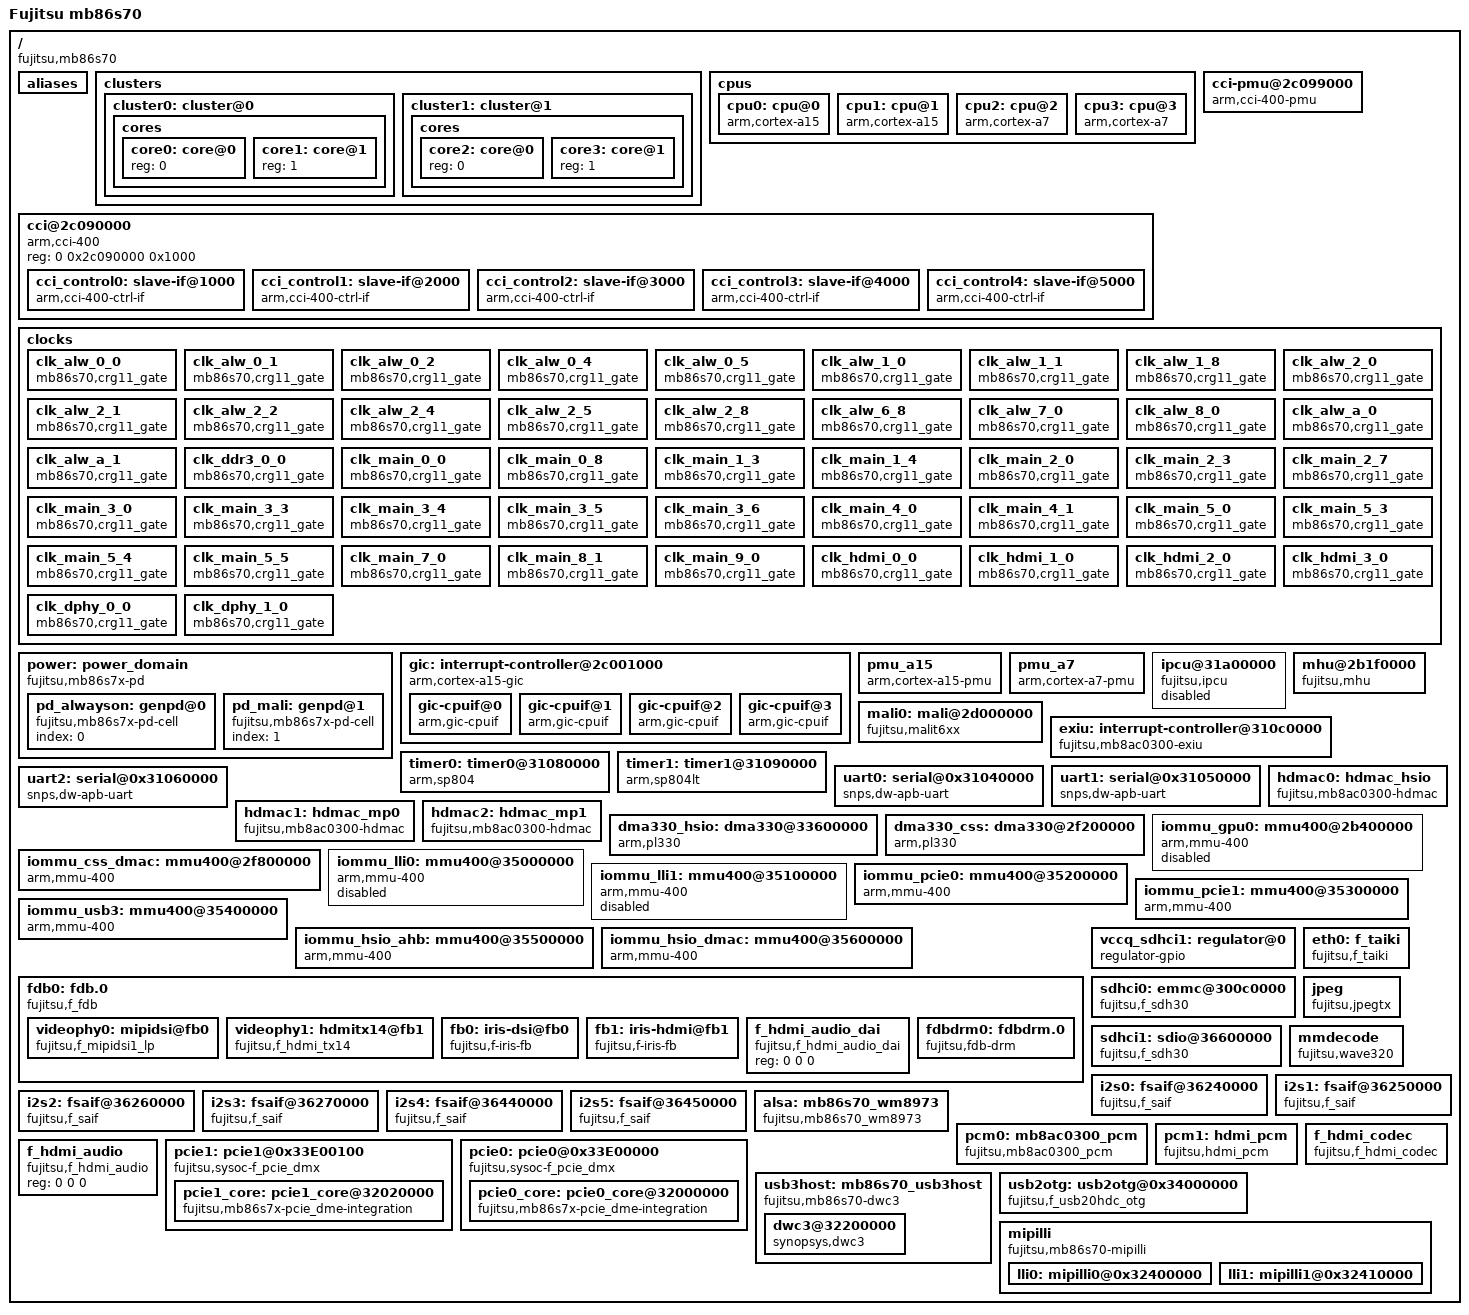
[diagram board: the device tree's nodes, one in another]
/*
 * Copyright (C) 2013-2015 Linaro, LTD for FUJITSU SEMICONDUCTOR LIMITED
 * Copyright (C) 2015-2016 Socionext Inc.
 *
 * This program is free software; you can redistribute it and/or modify
 * it under the terms of the GNU General Public License version 2 as
 * published by the Free Software Foundation.
 */

/ {
	model = "Fujitsu mb86s70";
	compatible = "fujitsu,mb86s70";
	interrupt-parent = <&gic>;
	#address-cells = <2>;
	#size-cells = <1>;

	aliases {
		serial0 = &uart0;
		serial1 = &uart1;
		serial2 = &uart2;
	};

	clusters {
		#address-cells = <1>;
		#size-cells = <0>;

		cluster0: cluster@0 { /* A15s */
			reg = <0>;
			freqs = <1600000000>;
			cores {
				#address-cells = <1>;
				#size-cells = <0>;

				core0: core@0 {
					reg = <0>;
				};

				core1: core@1 {
					reg = <1>;
				};
			};
		};

		cluster1: cluster@1 {
			reg = <1>;
			freqs = <800000000>;
			cores {
				#address-cells = <1>;
				#size-cells = <0>;
				core2: core@0 {
					reg = <0>;
				};

				core3: core@1 {
					reg = <1>;
				};
			};
		};
	};

	cpus {
		#address-cells = <1>;
		#size-cells = <0>;

		cpu0: cpu@0 {
			device_type = "cpu";
			compatible = "arm,cortex-a15";
			reg = <0>;
			cluster = <&cluster0>;
			core = <&core0>;
			cci-control-port = <&cci_control4>;
			clock-frequency = <1600000000>;
			operating-points = <
				1600000	1020000
			>;
			clock-latency = <1000000>;
		};

		cpu1: cpu@1 {
			device_type = "cpu";
			compatible = "arm,cortex-a15";
			reg = <1>;
			cluster = <&cluster0>;
			core = <&core1>;
			cci-control-port = <&cci_control4>;
			clock-frequency = <1600000000>;
			operating-points = <
				1600000	1020000
			>;
			clock-latency = <1000000>;
		};

		cpu2: cpu@2 {
			device_type = "cpu";
			compatible = "arm,cortex-a7";
			reg = <0x100>;
			cluster = <&cluster1>;
			core = <&core2>;
			cci-control-port = <&cci_control3>;
			clock-frequency = <800000000>;
			operating-points = <
				800000 900000
			>;
			clock-latency = <1000000>;
		};

		cpu3: cpu@3 {
			device_type = "cpu";
			compatible = "arm,cortex-a7";
			reg = <0x101>;
			cluster = <&cluster1>;
			core = <&core3>;
			cci-control-port = <&cci_control3>;
			clock-frequency = <800000000>;
			operating-points = <
				800000 900000
			>;
			clock-latency = <1000000>;
		};
	};

	cci@2c090000 {
		compatible = "arm,cci-400", "arm,cci";
		#address-cells = <1>;
		#size-cells = <1>;
		reg = <0 0x2c090000 0x1000>;
		ranges = <0x0 0x0 0x2c090000 0x10000>;

		cci_control0: slave-if@1000 {
			compatible = "arm,cci-400-ctrl-if";
			interface-type = "ace-lite";
			reg = <0x1000 0x1000>;
		};

		cci_control1: slave-if@2000 {
			compatible = "arm,cci-400-ctrl-if";
			interface-type = "ace-lite";
			reg = <0x2000 0x1000>;
		};

		cci_control2: slave-if@3000 {
			compatible = "arm,cci-400-ctrl-if";
			interface-type = "ace-lite";
			reg = <0x3000 0x1000>;
		};

		cci_control3: slave-if@4000 {
			compatible = "arm,cci-400-ctrl-if";
			interface-type = "ace";
			reg = <0x4000 0x1000>;
		};

		cci_control4: slave-if@5000 {
 			compatible = "arm,cci-400-ctrl-if";
 			interface-type = "ace";
 			reg = <0x5000 0x1000>;
 		};

	};

	cci-pmu@2c099000 {
		compatible = "arm,cci-400-pmu";
		reg = <0 0x2c099000 0x5000>;
		interrupts = <0 77 4>,
				<0 77 4>,
				<0 77 4>,
				<0 77 4>,
				<0 77 4>;
	};

	/**
	 * cntrlr : 0->ALW, 1->DDR3, 2->MAIN, 3->CA15, 4->HDMI, 5->DPHY
	 * port : [0,7] -> Gateable Clock Ports.  [8]->UngatedCLK
	 */
	clocks {
		clk_alw_0_0: clk_alw_0_0 {
			#clock-cells = <0>;
			compatible = "mb86s70,crg11_gate";
			cntrlr = <0>;
			domain = <0>;
			port = <0>;
		};
		clk_alw_0_1: clk_alw_0_1 {
			#clock-cells = <0>;
			compatible = "mb86s70,crg11_gate";
			cntrlr = <0>;
			domain = <0>;
			port = <1>;
		};
		clk_alw_0_2: clk_alw_0_2 {
			#clock-cells = <0>;
			compatible = "mb86s70,crg11_gate";
			cntrlr = <0>;
			domain = <0>;
			port = <2>;
		};
		clk_alw_0_4: clk_alw_0_4 {
			#clock-cells = <0>;
			compatible = "mb86s70,crg11_gate";
			cntrlr = <0>;
			domain = <0>;
			port = <4>;
		};
		clk_alw_0_5: clk_alw_0_5 {
			#clock-cells = <0>;
			compatible = "mb86s70,crg11_gate";
			cntrlr = <0>;
			domain = <0>;
			port = <5>;
		};
		clk_alw_1_0: clk_alw_1_0 {
			#clock-cells = <0>;
			compatible = "mb86s70,crg11_gate";
			cntrlr = <0>;
			domain = <1>;
			port = <0>;
		};
		clk_alw_1_1: clk_alw_1_1 {
			#clock-cells = <0>;
			compatible = "mb86s70,crg11_gate";
			cntrlr = <0>;
			domain = <1>;
			port = <1>;
		};
		clk_alw_1_8: clk_alw_1_8 {
			#clock-cells = <0>;
			compatible = "mb86s70,crg11_gate";
			cntrlr = <0>;
			domain = <1>;
			port = <8>;
		};
		clk_alw_2_0: clk_alw_2_0 {
			#clock-cells = <0>;
			compatible = "mb86s70,crg11_gate";
			cntrlr = <0>;
			domain = <2>;
			port = <0>;
		};
		clk_alw_2_1: clk_alw_2_1 {
			#clock-cells = <0>;
			compatible = "mb86s70,crg11_gate";
			cntrlr = <0>;
			domain = <2>;
			port = <1>;
		};
		clk_alw_2_2: clk_alw_2_2 {
			#clock-cells = <0>;
			compatible = "mb86s70,crg11_gate";
			cntrlr = <0>;
			domain = <2>;
			port = <2>;
		};
		clk_alw_2_4: clk_alw_2_4 {
			#clock-cells = <0>;
			compatible = "mb86s70,crg11_gate";
			cntrlr = <0>;
			domain = <2>;
			port = <4>;
		};
		clk_alw_2_5: clk_alw_2_5 {
			#clock-cells = <0>;
			compatible = "mb86s70,crg11_gate";
			cntrlr = <0>;
			domain = <2>;
			port = <5>;
		};
		clk_alw_2_8: clk_alw_2_8 {
			#clock-cells = <0>;
			compatible = "mb86s70,crg11_gate";
			cntrlr = <0>;
			domain = <2>;
			port = <8>;
		};
		clk_alw_6_8: clk_alw_6_8 {
			#clock-cells = <0>;
			compatible = "mb86s70,crg11_gate";
			cntrlr = <0>;
			domain = <6>;
			port = <8>;
		};

		clk_alw_7_0: clk_alw_7_0 {
			#clock-cells = <0>;
			compatible = "mb86s70,crg11_gate";
			cntrlr = <0>;
			domain = <7>;
			port = <0>;
		};
		clk_alw_8_0: clk_alw_8_0 {
			#clock-cells = <0>;
			compatible = "mb86s70,crg11_gate";
			cntrlr = <0>;
			domain = <8>;
			port = <0>;
		};
		clk_alw_a_0: clk_alw_a_0 {
			#clock-cells = <0>;
			compatible = "mb86s70,crg11_gate";
			cntrlr = <0>;
			domain = <0x0a>;
			port = <0>;
		};
		clk_alw_a_1: clk_alw_a_1 {
			#clock-cells = <0>;
			compatible = "mb86s70,crg11_gate";
			cntrlr = <0>;
			domain = <0x0a>;
			port = <1>;
		};
		clk_ddr3_0_0: clk_ddr3_0_0 {
			#clock-cells = <0>;
			compatible = "mb86s70,crg11_gate";
			cntrlr = <1>;
			domain = <0>;
			port = <0>;
		};

		clk_main_0_0: clk_main_0_0 {
			#clock-cells = <0>;
			compatible = "mb86s70,crg11_gate";
			cntrlr = <2>;
			domain = <0>;
			port = <0>;
		};
		clk_main_0_8: clk_main_0_8 {
			#clock-cells = <0>;
			compatible = "mb86s70,crg11_gate";
			cntrlr = <2>;
			domain = <0>;
			port = <8>;
		};
		clk_main_1_3: clk_main_1_3 {
			#clock-cells = <0>;
			compatible = "mb86s70,crg11_gate";
			cntrlr = <2>;
			domain = <1>;
			port = <3>;
		};
		clk_main_1_4: clk_main_1_4 {
			#clock-cells = <0>;
			compatible = "mb86s70,crg11_gate";
			cntrlr = <2>;
			domain = <1>;
			port = <4>;
		};
		clk_main_2_0: clk_main_2_0 {
			#clock-cells = <0>;
			compatible = "mb86s70,crg11_gate";
			cntrlr = <2>;
			domain = <2>;
			port = <0>;
		};
		clk_main_2_3: clk_main_2_3 {
			#clock-cells = <0>;
			compatible = "mb86s70,crg11_gate";
			cntrlr = <2>;
			domain = <2>;
			port = <3>;
		};
		clk_main_2_7: clk_main_2_7 {
			#clock-cells = <0>;
			compatible = "mb86s70,crg11_gate";
			cntrlr = <2>;
			domain = <2>;
			port = <7>;
		};
		clk_main_3_0: clk_main_3_0 {
			#clock-cells = <0>;
			compatible = "mb86s70,crg11_gate";
			cntrlr = <2>;
			domain = <3>;
			port = <0>;
		};
		clk_main_3_3: clk_main_3_3 {
			#clock-cells = <0>;
			compatible = "mb86s70,crg11_gate";
			cntrlr = <2>;
			domain = <3>;
			port = <3>;
		};
		clk_main_3_4: clk_main_3_4 {
			#clock-cells = <0>;
			compatible = "mb86s70,crg11_gate";
			cntrlr = <2>;
			domain = <3>;
			port = <4>;
		};
		clk_main_3_5: clk_main_3_5 {
			#clock-cells = <0>;
			compatible = "mb86s70,crg11_gate";
			cntrlr = <2>;
			domain = <3>;
			port = <5>;
		};
		clk_main_3_6: clk_main_3_6 {
			#clock-cells = <0>;
			compatible = "mb86s70,crg11_gate";
			cntrlr = <2>;
			domain = <3>;
			port = <6>;
		};
		clk_main_4_0: clk_main_4_0 {
			#clock-cells = <0>;
			compatible = "mb86s70,crg11_gate";
			cntrlr = <2>;
			domain = <4>;
			port = <0>;
		};
		clk_main_4_1: clk_main_4_1 {
			#clock-cells = <0>;
			compatible = "mb86s70,crg11_gate";
			cntrlr = <2>;
			domain = <4>;
			port = <1>;
		};
		clk_main_5_0: clk_main_5_0 {
			#clock-cells = <0>;
			compatible = "mb86s70,crg11_gate";
			cntrlr = <2>;
			domain = <5>;
			port = <0>;
		};
		clk_main_5_3: clk_main_5_3 {
			#clock-cells = <0>;
			compatible = "mb86s70,crg11_gate";
			cntrlr = <2>;
			domain = <5>;
			port = <3>;
		};
		clk_main_5_4: clk_main_5_4 {
			#clock-cells = <0>;
			compatible = "mb86s70,crg11_gate";
			cntrlr = <2>;
			domain = <5>;
			port = <4>;
		};
		clk_main_5_5: clk_main_5_5 {
			#clock-cells = <0>;
			compatible = "mb86s70,crg11_gate";
			cntrlr = <2>;
			domain = <5>;
			port = <5>;
		};
		clk_main_7_0: clk_main_7_0 {
			#clock-cells = <0>;
			compatible = "mb86s70,crg11_gate";
			cntrlr = <2>;
			domain = <7>;
			port = <0>;
		};
		clk_main_8_1: clk_main_8_1 {
			#clock-cells = <0>;
			compatible = "mb86s70,crg11_gate";
			cntrlr = <2>;
			domain = <8>;
			port = <1>;
		};
		clk_main_9_0: clk_main_9_0 {
			#clock-cells = <0>;
			compatible = "mb86s70,crg11_gate";
			cntrlr = <2>;
			domain = <9>;
			port = <0>;
		};
		clk_hdmi_0_0: clk_hdmi_0_0 {
			#clock-cells = <0>;
			compatible = "mb86s70,crg11_gate";
			cntrlr = <4>;
			domain = <0>;
			port = <0>;
		};
		clk_hdmi_1_0: clk_hdmi_1_0 {
			#clock-cells = <0>;
			compatible = "mb86s70,crg11_gate";
			cntrlr = <4>;
			domain = <1>;
			port = <0>;
		};
		clk_hdmi_2_0: clk_hdmi_2_0 {
			#clock-cells = <0>;
			compatible = "mb86s70,crg11_gate";
			cntrlr = <4>;
			domain = <2>;
			port = <0>;
		};
		clk_hdmi_3_0: clk_hdmi_3_0 {
			#clock-cells = <0>;
			compatible = "mb86s70,crg11_gate";
			cntrlr = <4>;
			domain = <3>;
			port = <0>;
		};

		clk_dphy_0_0: clk_dphy_0_0 {
			#clock-cells = <0>;
			compatible = "mb86s70,crg11_gate";
			cntrlr = <5>;
			domain = <0>;
			port = <0>;
		};
		clk_dphy_1_0: clk_dphy_1_0 {
			#clock-cells = <0>;
			compatible = "mb86s70,crg11_gate";
			cntrlr = <5>;
			domain = <1>;
			port = <0>;
		};
	};

	power: power_domain {
		compatible = "fujitsu,mb86s7x-pd";
		#power-domain-cells = <1>;
		#address-cells = <2>;
		#size-cells = <1>;
		ranges;

		pd_alwayson: genpd@0 {
			compatible = "fujitsu,mb86s7x-pd-cell";
			index = <0>;
		};
		pd_mali: genpd@1 {
			compatible = "fujitsu,mb86s7x-pd-cell";
			index = <1>;
		};
	};

	gic: interrupt-controller@2c001000 {
		compatible = "arm,cortex-a15-gic", "arm,cortex-a9-gic";
		#interrupt-cells = <3>;
		interrupt-controller;
		reg = <0 0x2c001000 0x1000>,
		      <0 0x2c002000 0x1000>,
		      <0 0x2c004000 0x2000>,
		      <0 0x2c006000 0x2000>;
		interrupts = <1 9 0xf04>;

		gic-cpuif@0 {
			compatible = "arm,gic-cpuif";
			cpuif-id = <0>;
			cpu = <&cpu0>;
		};
		gic-cpuif@1 {
			compatible = "arm,gic-cpuif";
			cpuif-id = <1>;
			cpu = <&cpu1>;
		};
		gic-cpuif@2 {
			compatible = "arm,gic-cpuif";
			cpuif-id = <2>;
			cpu = <&cpu2>;
		};
		gic-cpuif@3 {
			compatible = "arm,gic-cpuif";
			cpuif-id = <3>;
			cpu = <&cpu3>;
		};
	};

	pmu_a15 {
		compatible = "arm,cortex-a15-pmu";
		cluster  = <&cluster0>;
		interrupts = <0 2 4>,
			     <0 6 4>;
	};

	pmu_a7 {
		compatible = "arm,cortex-a7-pmu";
		cluster  = <&cluster1>;
		interrupts = <0 18 4>,
			     <0 22 4>;
	};

	ipcu@31a00000 {
		#clock-cells = <1>;
		compatible = "fujitsu,ipcu";
		status = "disabled";
		mboxes = <8>;
		reg = <0 0x31A00000 0x960>;
		interrupts = <0 152 4>, /* A15 CPU 0 */
			     <0 153 4>, /* A15 CPU 1 */
			     <0 154 4>,
			     <0 155 4>,
			     <0 156 4>, /* A7 CPU 0 */
			     <0 157 4>, /* A7 CPU 1 */
			     <0 158 4>,
			     <0 159 4>;
		clocks = <&clk_alw_2_1>;
	};

	mhu@2b1f0000 {
		compatible = "fujitsu,mhu";
		reg = <0 0x2B1F0000 0x1000>;
		interrupts = <0 36 4>, /* LP Non-Sec */
			     <0 35 4>, /* HP Non-Sec */
			     <0 37 4>; /* Secure */
		clocks = <&clk_alw_2_1>;
		clock-names = "clk";
	};

	mali0: mali@2d000000 {
		compatible = "fujitsu,malit6xx";
		reg = <0 0x2d000000 0x10000>;
		interrupts = <0 33 4>, /* Mali JOB */
			     <0 34 4>, /* Mali MMU */
			     <0 32 4>; /* Mali GPU */
                interrupt-names = "JOB", "MMU", "GPU";
		clocks = <&clk_main_7_0>, <&clk_main_2_0>, <&clk_main_0_0>, <&clk_main_4_0>;
		clock-names = "g3d", "aclk_g3d", "mout_gpll", "fout_gpll";
		#stream-id-cells = <0>;
		power-domains = <&power 1>;
		cci-control-port = <&cci_control2>;
	};

	exiu: interrupt-controller@310c0000 {
		compatible = "fujitsu,mb8ac0300-exiu";
		reg = <0 0x310c0000 0x1000>;
		exiu_irq_base0 = <112>;
		exiu_irq_base1 = <128>;
		clocks = <&clk_alw_2_1>;
	};

	timer0: timer0@31080000 {
		#clock-cells = <1>;
		compatible = "arm,sp804";
		reg = <0 0x31080000 0x10000>;
		interrupts = <0 324 4>,
			     <0 325 4>;
		clocks = <&clk_alw_6_8>;
	};

	timer1: timer1@31090000 {
		#clock-cells = <1>;
		compatible = "arm,sp804lt";
		reg = <0 0x31090000 0x20000>;
		interrupts = <0 328 4>,
			     <0 329 4>,
			     <0 332 4>,
			     <0 333 4>;
		clocks = <&clk_alw_6_8>;
	};

	uart0: serial@0x31040000 {
		#clock-cells = <1>;
		compatible = "snps,dw-apb-uart";
		reg = <0 0x31040000 0x100>;
		interrupts = <0 320 0x4>;
		clock-frequency = <62500000>;
		reg-io-width = <4>;
		reg-shift = <2>;
		clocks = <&clk_alw_2_1>;
		clock-names = "sclk";
	};

	uart1: serial@0x31050000 {
		#clock-cells = <1>;
		compatible = "snps,dw-apb-uart";
		reg = <0 0x31050000 0x100>;
		interrupts = <0 321 0x4>;
		clock-frequency = <62500000>;
		reg-io-width = <4>;
		reg-shift = <2>;
		clocks = <&clk_alw_2_1>;
		clock-names = "sclk";
	};

	uart2: serial@0x31060000 {
		#clock-cells = <1>;
		compatible = "snps,dw-apb-uart";
		reg = <0 0x31060000 0x100>;
		interrupts = <0 322 0x4>;
		clock-frequency = <62500000>;
		reg-io-width = <4>;
		reg-shift = <2>;
		clocks = <&clk_alw_2_1>;
		clock-names = "sclk";
	};

	hdmac0: hdmac_hsio {
		compatible = "fujitsu,mb8ac0300-hdmac";
		reg = <0 0x34080000 0x1000>;
		interrupts = <0 128 0x4>,
			     <0 129 0x4>;
		clocks = <&clk_alw_2_1>, <&clk_main_2_3>;
		channels = <2>;
		chip = <0>;
		rotation = <1>;
	};

	hdmac1: hdmac_mp0 {
		compatible = "fujitsu,mb8ac0300-hdmac";
		reg = <0 0x36200000 0x1000>;
		interrupts = <0 112 0x4>,
			     <0 113 0x4>,
			     <0 114 0x4>,
			     <0 115 0x4>,
			     <0 116 0x4>,
			     <0 117 0x4>,
			     <0 118 0x4>,
			     <0 119 0x4>;
		clocks = <&clk_main_3_6>;
		channels = <8>;
		chip = <1>;
		rotation = <1>;
	};

	hdmac2: hdmac_mp1 {
		compatible = "fujitsu,mb8ac0300-hdmac";
		reg = <0 0x36400000 0x1000>;
		interrupts = <0 120 0x4>,
			     <0 121 0x4>,
			     <0 122 0x4>,
			     <0 123 0x4>;
		clocks = <&clk_main_3_6>;
		channels = <4>;
		chip = <2>;
		rotation = <1>;
	};

	dma330_hsio: dma330@33600000 {
		compatible = "arm,pl330", "arm,primecell";
		reg = <0 0x33600000 0x1000>;
		interrupts = <0 144 4>,
				<0 145 4>,
				<0 146 4>,
				<0 147 4>;
		clocks = <&clk_main_0_8>;
		clock-names = "apb_pclk";
		copy-align = <128>;
		#dma-cells = <1>;
		#dma-channels = <4>;
		#dma-requests = <1>;
		#stream-id-cells = <2>;
		iova-start = <0x00000000>;
		iova-range = <0x1 0x00000000>;
	};

	dma330_css: dma330@2f200000 {
		compatible = "arm,pl330", "arm,primecell";
		reg = <0 0x2f200000 0x1000>;
		interrupts = <0 136 4>,
				<0 137 4>,
				<0 138 4>,
				<0 139 4>,
				<0 140 4>,
				<0 141 4>,
				<0 142 4>,
				<0 143 4>;
		clocks = <&clk_main_0_8>;
		clock-names = "apb_pclk";
		copy-align = <128>;
		#dma-cells = <1>;
		#dma-channels = <8>;
		#dma-requests = <32>;
		#stream-id-cells = <2>;
		iova-start = <0x00000000>;
		iova-range = <0x1 0x00000000>;
	};

	iommu_gpu0: mmu400@2b400000 {
		status = "disabled";
		compatible = "arm,mmu-400";
		reg = <0 0x2b400000 0x10000>;
		#global-interrupts = <1>;
		interrupts = <0 38 4>, <0 39 4>;
		mmu-masters = <&mali0>;
		stream-ids = <0>;
	};
	iommu_css_dmac: mmu400@2f800000 {
		compatible = "arm,mmu-400";
		reg = <0 0x2f800000 0x10000>;
		#global-interrupts = <1>;
		interrupts = <0 64 4>, <0 65 4>;
		mmu-masters = <&dma330_css 0 1>;
		coherent_table_walk;
		stream-ids = <0>;
	};
	iommu_lli0: mmu400@35000000 {
		status = "disabled";
		compatible = "arm,mmu-400";
		reg = <0 0x35000000 0x10000>;
		#global-interrupts = <1>;
		interrupts = <0 66 4>, <0 67 4>;
		mmu-masters = <&lli0>;
		stream-ids = <0>;
	};
	iommu_lli1: mmu400@35100000 {
		status = "disabled";
		compatible = "arm,mmu-400";
		reg = <0 0x35100000 0x10000>;
		#global-interrupts = <1>;
		interrupts = <0 68 4>, <0 69 4>;
		mmu-masters = <&lli1>;
		stream-ids = <0>;
	};
	iommu_pcie0: mmu400@35200000 {
		compatible = "arm,mmu-400";
		reg = <0 0x35200000 0x10000>;
		#global-interrupts = <1>;
		interrupts = <0 71 4>, <0 70 4>;
		mmu-masters = <&pcie0 0 1>;
		stream-ids = <0>;
	};
	iommu_pcie1: mmu400@35300000 {
		compatible = "arm,mmu-400";
		reg = <0 0x35300000 0x10000>;
		#global-interrupts = <1>;
		interrupts = <0 73 4>, <0 72 4>;
		mmu-masters = <&pcie1 0 1>;
		stream-ids = <0>;
	};
	iommu_usb3: mmu400@35400000 {
		compatible = "arm,mmu-400";
		reg = <0 0x35400000 0x10000>;
		#global-interrupts = <1>;
		interrupts = <0 75 4>, <0 74 4>;
		mmu-masters = <&usb3host 0 1>;
		stream-ids = <0>;
	};
	iommu_hsio_ahb: mmu400@35500000 {
		compatible = "arm,mmu-400";
		reg = <0 0x35500000 0x10000>;
		#global-interrupts = <1>;
		interrupts = <0 77 4>, <0 76 4>;
		mmu-masters = <&usb2otg 0 1>;
		stream-ids = <0>, <0>;
	};
	iommu_hsio_dmac: mmu400@35600000 {
		compatible = "arm,mmu-400";
		reg = <0 0x35600000 0x10000>;
		#global-interrupts = <1>;
		interrupts = <0 79 4>, <0 78 4>;
		mmu-masters = <&dma330_hsio 0 1>;
		stream-ids = <0>;
	};

	fdb0: fdb.0 {
		compatible = "fujitsu,f_fdb",
			     "simple-bus";
		id = <0>;
		#address-cells = <2>;
		#size-cells = <1>;
		#stream-id-cells = <2>;
		iova-start = <0x90000000>;
		iova-range = <0x0 0x50000000>;
		ranges;

		/* dsi PHY --  IP2 doc p453 */
		videophy0: mipidsi@fb0 {
			compatible = "fujitsu,f_mipidsi1_lp";
			reg = <0 0x37700000 0x8000>;
			interrupts = <0 305 0x4>;
			sources = <1>; /* bitfield of fbs can be driven by */
			clocks = <&clk_dphy_0_0>, <&clk_dphy_1_0>, <&clk_main_5_3>;
			clock-names = "pllclk", "dpiclk", "pclk";
			simple-bind = <&fb0>;
		};

		/* hdmi PHY -- IP2 doc p71 */
		videophy1: hdmitx14@fb1 {
			compatible = "fujitsu,f_hdmi_tx14";
			reg = <0 0x37600000 0x8000>;
			interrupts = <0 304 0x4>;
			sources = <2>; /* bitfield of fbs can be driven by */
			clocks = <&clk_hdmi_0_0>, <&clk_main_5_0>, <&clk_hdmi_1_0>;
			clock-names = "pllclk", "pclk", "dpiclk";
			simple-bind = <&fb1>;
		};


		/* DSI IRIS */
		fb0: iris-dsi@fb0 {
			compatible = "fujitsu,f-iris-fb";
			reg = <0 0x37020000 0x8000>;
			interrupts = <0 212 0x4>,
				     <0 213 0x4>,
				     <0 214 0x4>,
				     <0 215 0x4>,
				     <0 216 0x4>,
				     <0 217 0x4>,
				     <0 218 0x4>,
				     <0 219 0x4>,
				     <0 220 0x4>,
				     <0 221 0x4>,
				     <0 222 0x4>,
				     <0 223 0x4>,
				     <0 224 0x4>,
				     <0 225 0x4>,
				     <0 226 0x4>,
				     <0 227 0x4>;
			id = <0>;
			simple = <0>;
			perf-mode = <1>;
			/* EVB LCD timings / resolution (mipidsi) */
			mode = "768x1280x32bpp"; /* 768x1280x16bpp also possible */
			/* not possible to offset start of dsi px stream, have to offset fb start */
			h-pixels-fb-offset = <12>;
			clocks = <&clk_dphy_1_0>, <&clk_main_1_3>, <&clk_main_3_3>;
			clock-names = "clk1", "clk2", "clk3";
		};

		/* HDMI IRIS */
		fb1: iris-hdmi@fb1 {
			status = "okay";
			compatible = "fujitsu,f-iris-fb";
			reg = <0 0x37000000 0x8000>;
			interrupts = <0 192 0x4>,
				     <0 193 0x4>,
				     <0 194 0x4>,
				     <0 195 0x4>,
				     <0 196 0x4>,
				     <0 197 0x4>,
				     <0 198 0x4>,
				     <0 199 0x4>,
				     <0 200 0x4>,
				     <0 201 0x4>,
				     <0 202 0x4>,
				     <0 203 0x4>,
				     <0 204 0x4>,
				     <0 205 0x4>,
				     <0 206 0x4>,
				     <0 207 0x4>;
			id = <1>;
			simple = <0>;
			perf-mode = <1>;
			/* colourbars = <1>; */
			clocks = <&clk_hdmi_0_0>, <&clk_hdmi_1_0>, <&clk_main_1_4>, <&clk_main_3_4>, <&clk_main_5_4>, <&clk_alw_7_0>, <&clk_alw_8_0>;
			clock-names = "clk1", "clk2", "clk3", "clk4", "clk5", "clk6", "clk7";
		};

		f_hdmi_audio_dai: f_hdmi_audio_dai {
			compatible = "fujitsu,f_hdmi_audio_dai";
			reg = <0 0 0>;
		};

		fdbdrm0: fdbdrm.0 {
			status = "okay";
			compatible = "fujitsu,fdb-drm";
			bind = <&fb0>, <&fb1>;
			registrations = <4>; /* wait for this many children */
			default-bpp = <32>; /* set to 16 if 16-bit LCD mode selected */
		};
	};

	vccq_sdhci1: regulator@0 {
		compatible = "regulator-gpio";
		regulator-name = "SDHCI1 VccQ";
		regulator-min-microvolt = <1800000>;
		regulator-max-microvolt = <3300000>;
		gpios = <&gpio0 7 0>;
		gpios-states = <1>;
		states = <3300000 1
			  1800000 0>;
	};

	sdhci0: emmc@300c0000 {
		compatible = "fujitsu,f_sdh30";
		reg = <0 0x300c0000 0x1000>;
		interrupts = <0 164 0x4>,
			     <0 165 0x4>;
		bus-width = <8>;
		clocks = <&clk_alw_1_8>, <&clk_alw_6_8>;
		clock-names = "sd_sd4clk", "sd_bclk";
		tuning_count_default = <0xA>;
	};

	sdhci1: sdio@36600000 {
		compatible = "fujitsu,f_sdh30";
		reg = <0 0x36600000 0x1000>;
		interrupts = <0 172 0x4>,
			     <0 173 0x4>;
		vqmmc-supply = <&vccq_sdhci1>;
		/*
		 * bitmap of EVB board revisions lacking 1.8V capability
		 * b0 = rev 0, b1 = rev 1, etc
		 */
		revs-no-1v8 = <1>;
		inverted-write-protect;
		clocks = <&clk_hdmi_2_0>, <&clk_hdmi_3_0>;
		clock-names = "sd_sd4clk", "sd_bclk";
		#stream-id-cells = <2>;
		iova-start = <0x90000000>;
		iova-range = <0x0 0x50000000>;
		tuning_count_default = <0xA>;
	};

	eth0: f_taiki {
                compatible = "fujitsu,f_taiki";
                id = <0>;
                default_mac = < 0xa4 0x17 0x31 0x00 0x00 0xed >;
		reg = <0 0x31600000 0x10000>;
		interrupts = <0 163 0x4>;
		/* fake clocks */
		clocks = <&clk_alw_1_8>, <&clk_alw_1_8>, <&clk_alw_1_8>;
		clock-names = "h_clk", "osc_clk", "pclk";
		phy-interface = "RGMII";
		phy-dev-addr = <1>;
		phy-status-poll-interval-ms = <500>;
		link-speed = "1G";
		half-duplex = <0>;
		flow-control = <1>;
		use-jumbo = <1>;
		gpio-phy-enable = <14>;
		gpio-phy-nrst = <13>;
	};

	jpeg: jpeg {
		compatible = "fujitsu,jpegtx";
		reg = <0 0x36020000 0x10000>;
		id = <0>;
		interrupts = <0 190 0x4>;
		clocks = <&clk_main_5_5>, <&clk_main_8_1>;
		clock-names = "clk1", "clk2";
		memory-size = <0x01000000>; /* 16MB */
		#stream-id-cells = <2>;
		iova-start = <0x90000000>;
		iova-range = <0x0 0x50000000>;
	};

	mmdecode: mmdecode {
		compatible = "fujitsu,wave320";
		reg = <0 0x36000000 0x20000>;
		id = <0>;
		interrupts = <0 188 0x4>,
			     <0 189 0x4>;
		clocks = <&clk_main_5_5>, <&clk_main_8_1>;
		clock-names = "clk1", "clk2";
		memory-size = <0x04000000>; /* 64MB */
		#stream-id-cells = <2>;
		iova-start = <0x90000000>;
		iova-range = <0x0 0x50000000>;
	};

	i2s0: fsaif@36240000 {
		compatible = "fujitsu,f_saif";
		reg = <0 0x36240000 0x1000>;
		interrupts = <0 180 0x4>;
		clocks = <&clk_main_3_5>;
	};

	i2s1: fsaif@36250000 {
		compatible = "fujitsu,f_saif";
		reg = <0 0x36250000 0x1000>;
		interrupts = <0 181 0x4>;
		clocks = <&clk_main_3_5>;
	};

	i2s2: fsaif@36260000 {
		compatible = "fujitsu,f_saif";
		reg = <0 0x36260000 0x1000>;
		interrupts = <0 182 0x4>;
		clocks = <&clk_main_3_5>;
	};

	i2s3: fsaif@36270000 {
		compatible = "fujitsu,f_saif";
		reg = <0 0x36270000 0x1000>;
		interrupts = <0 183 0x4>;
		clocks = <&clk_main_3_5>;
	};

	i2s4: fsaif@36440000 {
		compatible = "fujitsu,f_saif";
		reg = <0 0x36440000 0x1000>;
		interrupts = <0 184 0x4>;
		clocks = <&clk_main_3_6>;
	};

	i2s5: fsaif@36450000 {
		compatible = "fujitsu,f_saif";
		reg = <0 0x36450000 0x1000>;
		interrupts = <0 185 0x4>;
		clocks = <&clk_main_3_6>;
	};

	alsa: mb86s70_wm8973 {
		compatible = "fujitsu,mb86s70_wm8973";
		reg = <0 0 0>; /* fake to stop xx.123 disease */
		channel = <0>;
		ms_mode = <0x4000>; // SND_SOC_DAIFMT_CBS_CFS
		format = <1>; // SND_SOC_DAIFMT_I2S
		use_eclk = <1>; // 0 = AHB
		sound-dai = <&pcm0>;
		#stream-id-cells = <2>;
		iova-start = <0x90000000>;
		iova-range = <0x0 0x50000000>;
	};

	pcm0: mb8ac0300_pcm {
		reg = <0 0 0>; /* fake to stop xx.123 disease */
		compatible = "fujitsu,mb8ac0300_pcm";
		/* which hdmac chip we are hooked to */
		hdmac = <2>;
		/* which periperhal dma request lines we are hooked to */
		hdmac-trig-pid-capture =  <0x11000000>; /* HDMACA_IS_IDREQ1H */
		hdmac-trig-pid-playback = <0x12000000>; /* HDMACA_IS_IDREQ2H */
	};

	pcm1: hdmi_pcm {
		reg = <0 0 0>; /* fake to stop xx.123 disease */
		compatible = "fujitsu,hdmi_pcm";
		/* which hdmac chip we are hooked to */
		hdmac = <1>;
		/* which periperhal dma request lines we are hooked to */
		hdmac-hdmi-i2s0 = <0x10000000>; /* HDMACA_IS_IDREQ0H */
		hdmac-hdmi-i2s1 = <0x12000000>; /* HDMACA_IS_IDREQ2H */
		hdmac-hdmi-i2s2 = <0x14000000>; /* HDMACA_IS_IDREQ4H */
		hdmac-hdmi-i2s3 = <0x16000000>; /* HDMACA_IS_IDREQ6H */
	};

	f_hdmi_codec: f_hdmi_codec {
		compatible = "fujitsu,f_hdmi_codec";
		reg = <0 0 0>;
		sound-dai = <&pcm1>;
	};

	f_hdmi_audio: f_hdmi_audio {
		compatible = "fujitsu,f_hdmi_audio";
		reg = <0 0 0>;
	};

	pcie1:pcie1@0x33E00100 {
		compatible = "fujitsu,sysoc-f_pcie_dmx";
		#address-cells = <2>;
		#size-cells = <1>;
		id = <1>;
		ranges;
		reg = <0 0x33E00100 0x64>;
		clock_num = <1>;
		clock-names = "pcie1_hclk";
		clocks = <&clk_alw_2_2>;
		phy_reset;
		#stream-id-cells = <2>;
		iova-start = <0x00000000>;
		iova-range = <0x1 0x00000000>;

		pcie1_core: pcie1_core@32020000 {
			compatible = "fujitsu,mb86s7x-pcie_dme-integration";
			ven_dev_id = <0x10cf 0x2042>;
			reg = <0 0x32020000 0x20000>;
			interrupts = <0 260 4>, <0 261 4>, <0 262 4>, <0 263 4>,
				<0 264 4>, <0 267 4>, <0 269 4>, <0 270 4>,
				<0 271 4>, <0 272 4>;
			dma_int_off = <6>;
			pme_int_off = <4>;
			clocks = <&clk_alw_0_0>,<&clk_alw_0_2>,<&clk_alw_2_0>;
			clock-names = "bus_pcie_aclk","pcie1_aclk","pcie_pclk";
			clock_num = <3>;
			link_spd = <1>; /* 0=>2.5GT/s, 1=>2.5GT/s and 5.0GT/s */
			link_wid = <4>; /* 1=> max land x1, 4=> max land x4 */
			#address-cells = <3>;
			#size-cells = <2>;
			ranges = <0x01000000 0x0 0x00000000 0x0 0x58000000 0 0x08000000
					0x02000000 0x0 0x00000000 0x0 0x70000000 0 0x04000000
					0x02000000 0x0 0x04000000 0x0 0x74000000 0 0x04000000
					0x02000000 0x0 0x08000000 0x0 0x78000000 0 0x04000000
					0x02000000 0x0 0x0C000000 0x0 0x7C000000 0 0x02000000
					0x03000000 0x0 0x40000000 0x6 0x40000000 0 0x40000000
					0x03000000 0x0 0x80000000 0x6 0x80000000 0 0x40000000
					0x00000000 0x0 0xC0000000 0x0 0x32060000 0 0x00010000>;
		};
	};

	pcie0:pcie0@0x33E00000 {
		compatible = "fujitsu,sysoc-f_pcie_dmx";
		#address-cells = <2>;
		#size-cells = <1>;
		ranges;
		id = <0>;
		reg = <0 0x33E00000 0x64>;
		clock_num = <1>;
		clock-names = "pcie0_hclk";
		clocks = <&clk_alw_2_1>;
		phy_reset;
		#stream-id-cells = <2>;
		iova-start = <0x00000000>;
		iova-range = <0x1 0x00000000>;

		pcie0_core: pcie0_core@32000000 {
			compatible = "fujitsu,mb86s7x-pcie_dme-integration";
			reg = <0 0x32000000 0x20000>;
			interrupts = <0 240 4>, <0 241 4>, <0 242 4>, <0 243 4>,
				<0 244 4>, <0 247 4>, <0 249 4>, <0 250 4>,
				<0 251 4>, <0 252 4>;
			dma_int_off = <6>;
			pme_int_off = <4>;
			clocks = <&clk_alw_0_0>,<&clk_alw_0_1>,<&clk_alw_2_0>;
			clock-names = "bus_pcie_aclk","pcie0_aclk","pcie_pclk";
			clock_num = <3>;
			link_spd = <1>; /* 0=>2.5GT/s, 1=>2.5GT/s and 5.0GT/s */
			link_wid = <4>; /* 1=> max land x1, 4=> max land x4 */
			/* ranges = <phys.hi phys.mid phys.low cpu range */
			#address-cells = <3>;
			#size-cells = <2>;
			ranges = <0x01000000 0x0 0x00000000 0x0 0x50000000 0 0x08000000
					0x02000000 0x0 0x00000000 0x0 0x60000000 0 0x04000000
					0x02000000 0x0 0x02000000 0x0 0x64000000 0 0x04000000
					0x02000000 0x0 0x08000000 0x0 0x68000000 0 0x04000000
					0x02000000 0x0 0x0C000000 0x0 0x6C000000 0 0x04000000
					0x03000000 0x0 0x40000000 0x4 0x40000000 0 0x40000000
					0x03000000 0x0 0x80000000 0x4 0x80000000 0 0x40000000
					0x00000000 0x0 0xC0000000 0x0 0x32040000 0 0x00010000>;
		};
	};

	usb3host: mb86s70_usb3host {
		compatible = "fujitsu,mb86s70-dwc3";
		reg = <0 0x32200000 0x100000>;
		clocks = <&clk_alw_1_1>;/*<&clk_main_4_1> will crash SCB*/
		clock-names = "bus_clk";/*"pclk"*/
		#address-cells = <2>;
		#size-cells = <1>;
		ranges;
		#stream-id-cells = <2>;
		iova-start = <0x00000000>;
		iova-range = <0x1 0x00000000>;

		dwc3@32200000 {
			compatible = "synopsys,dwc3";
			reg = <0 0x32200000 0x100000>;
			interrupts = <0 292 0x4>,
			             <0 294 0x4>;
			disconnection-quirk;
		};
	};

	usb2otg: usb2otg@0x34000000 {
		compatible = "fujitsu,f_usb20hdc_otg";
		mode = <2>; /* 0:host-only, 1:gadget-only, 2:dual-mode */
		reg = <0 0x34000000 0x10000>;
		interrupts = <0 296 0x4>;
		dma_dreq = <0x10000000 0x11000000>;
		hdmac_channel = <0 1>;
		clocks = <&clk_main_2_3>;
		clock-names = "h_clk";
		#stream-id-cells = <2>;
		iova-start = <0x80000000>;
		iova-range = <0x0 0x80000000>;
	};

	mipilli {
		compatible = "fujitsu,mb86s70-mipilli";
		iova-start = <0x00000000>;
		iova-range = <0x1 0x00000000>;
		#address-cells = <2>;
		#size-cells = <1>;
		ranges;
		lli0: mipilli0@0x32400000{
			id = <0>;
			reg = <0 0x32400000 0x10000>;
			interrupts = <0 232 0x4>;
			irq-name = "lli-0";
			clocks = <&clk_alw_0_4>, <&clk_alw_2_4>, <&clk_alw_a_0>;
			clock-names = "aclk", "pclk", "tx_bit_clk";
			#stream-id-cells = <0>;
		};
		lli1: mipilli1@0x32410000{
			id = <1>;
			reg = <0 0x32410000 0x10000>;
			interrupts = <0 236 0x4>;
			irq-name = "lli-1";
			clocks = <&clk_alw_0_5>, <&clk_alw_2_5>, <&clk_alw_a_1>;
			clock-names = "aclk", "pclk", "tx_bit_clk";
			#stream-id-cells = <0>;
		};
	};
};
